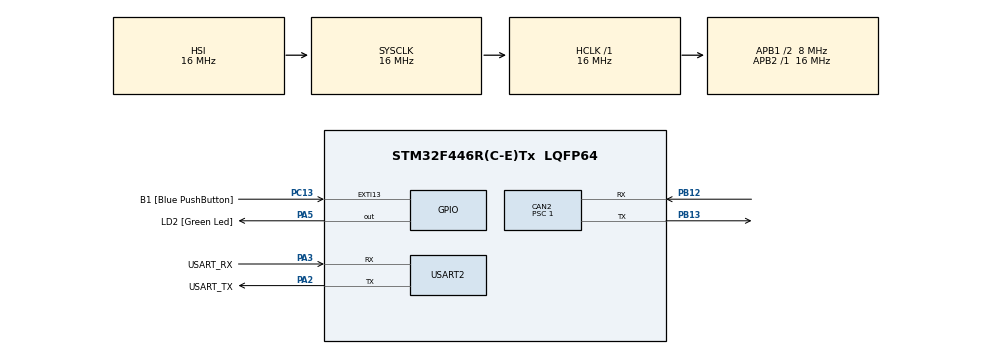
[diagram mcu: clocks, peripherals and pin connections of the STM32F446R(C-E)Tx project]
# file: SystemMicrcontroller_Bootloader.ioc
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Mcu.Family=STM32F4
PC15-OSC32_OUT.Mode=LSE-External-Oscillator
CAN2.CalculateBaudRate=500000
PH0-OSC_IN.Signal=RCC_OSC_IN
RCC.CortexFreq_Value=16000000
CAN2.CalculateTimeBit=2000.00
PC13.Signal=GPXTI13
PA14.GPIO_Label=TCK
PC13.GPIO_Label=B1 [Blue PushButton]
RCC.APB1CLKDivider=RCC_HCLK_DIV2
PC14-OSC32_IN.Signal=RCC_OSC32_IN
PB13.Signal=CAN2_TX
ProjectManager.StackSize=0x400
PA13.Signal=SYS_JTMS-SWDIO
PA3.Mode=Asynchronous
ProjectManager.TargetToolchain=STM32CubeIDE
RCC.HCLKFreq_Value=16000000
RCC.APB2TimFreq_Value=16000000
RCC.USBFreq_Value=168000000
PC15-OSC32_OUT.Signal=RCC_OSC32_OUT
RCC.AHBFreq_Value=16000000
PH0-OSC_IN.Mode=HSE-External-Oscillator
PA5.Signal=GPIO_Output
RCC.HSE_VALUE=8000000
board=NUCLEO-F446RE
RCC.VCOOutputFreq_Value=336000000
RCC.APB2Freq_Value=16000000
PC14-OSC32_IN.Mode=LSE-External-Oscillator
PA14.Mode=Serial_Wire
CAN2.Prescaler=1
CAN2.CalculateTimeQuantum=125.0
PH1-OSC_OUT.Signal=RCC_OSC_OUT
PA13.Mode=Serial_Wire
Mcu.Name=STM32F446R(C-E)Tx
PA2.Signal=USART2_TX
PA13.GPIO_Label=TMS
RCC.FLatency-AdvancedSettings=FLASH_LATENCY_0
PH1-OSC_OUT.Mode=HSE-External-Oscillator
RCC.48MHZClocksFreq_Value=84000000
PB3.Signal=SYS_JTDO-SWO
RCC.SYSCLKFreq_VALUE=16000000
Mcu.Package=LQFP64
PB12.Mode=CAN_Activate
CAN2.BS1=CAN_BS1_13TQ
PA5.GPIO_Label=LD2 [Green Led]
CAN2.BS2=CAN_BS2_2TQ
PC13.GPIO_ModeDefaultEXTI=GPIO_MODE_IT_FALLING
USART2.VirtualMode=VM_ASYNC
PA2.GPIO_Label=USART_TX
PA14.Signal=SYS_JTCK-SWCLK
ProjectManager.HeapSize=0x200
RCC.HSI_VALUE=16000000
RCC.PLLP=RCC_PLLP_DIV4
NVIC.PriorityGroup=NVIC_PRIORITYGROUP_0
RCC.PLLN=336
RCC.APB1TimFreq_Value=16000000
PA2.Mode=Asynchronous
PB13.Mode=CAN_Activate
RCC.APB1Freq_Value=8000000
VP_CRC_VS_CRC.Mode=CRC_Activate
PB12.Signal=CAN2_RX
PA3.GPIO_Label=USART_RX
PA3.Signal=USART2_RX
PB3.GPIO_Label=SWO

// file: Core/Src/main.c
/* USER CODE BEGIN Header */
/**
  ******************************************************************************
  * @file           : main.c
  * @brief          : Main program body
  ******************************************************************************
  * @attention
  *
  * <h2><center>&copy; Copyright (c) 2021 STMicroelectronics.
  * All rights reserved.</center></h2>
  *
  * This software component is licensed by ST under BSD 3-Clause license,
  * the "License"; You may not use this file except in compliance with the
  * License. You may obtain a copy of the License at:
  *                        opensource.org/licenses/BSD-3-Clause
  *
  ******************************************************************************
  */
/* USER CODE END Header */
#include "main.h"
#include "can.h"
#include "crc.h"
#include "usart.h"
#include "gpio.h"

/* USER CODE BEGIN Includes */
#include "SystemTruckBL_main.h"
/* USER CODE END Includes */

void SystemClock_Config(void);

int main(void)
{

  /* MCU Configuration--------------------------------------------------------*/

  /* Reset of all peripherals, Initializes the Flash interface and the Systick. */
  HAL_Init();

  /* Configure the system clock */
  SystemClock_Config();

  /* Initialize all configured peripherals */
  MX_GPIO_Init();
  MX_USART2_UART_Init();
  MX_CAN2_Init();
  MX_CRC_Init();
  /* USER CODE BEGIN 2 */
  SystemTruckBL_main();
  /* USER CODE END 2 */

  /* Infinite loop */
  while (1)
  {

  }
}

void SystemClock_Config(void)
{
  RCC_OscInitTypeDef RCC_OscInitStruct = {0};
  RCC_ClkInitTypeDef RCC_ClkInitStruct = {0};

  /** Configure the main internal regulator output voltage
  */
  __HAL_RCC_PWR_CLK_ENABLE();
  __HAL_PWR_VOLTAGESCALING_CONFIG(PWR_REGULATOR_VOLTAGE_SCALE3);
  /** Initializes the RCC Oscillators according to the specified parameters
  * in the RCC_OscInitTypeDef structure.
  */
  RCC_OscInitStruct.OscillatorType = RCC_OSCILLATORTYPE_HSI;
  RCC_OscInitStruct.HSIState = RCC_HSI_ON;
  RCC_OscInitStruct.HSICalibrationValue = RCC_HSICALIBRATION_DEFAULT;
  RCC_OscInitStruct.PLL.PLLState = RCC_PLL_NONE;
  if (HAL_RCC_OscConfig(&RCC_OscInitStruct) != HAL_OK)
  {
    Error_Handler();
  }
  /** Initializes the CPU, AHB and APB buses clocks
  */
  RCC_ClkInitStruct.ClockType = RCC_CLOCKTYPE_HCLK|RCC_CLOCKTYPE_SYSCLK
                              |RCC_CLOCKTYPE_PCLK1|RCC_CLOCKTYPE_PCLK2;
  RCC_ClkInitStruct.SYSCLKSource = RCC_SYSCLKSOURCE_HSI;
  RCC_ClkInitStruct.AHBCLKDivider = RCC_SYSCLK_DIV1;
  RCC_ClkInitStruct.APB1CLKDivider = RCC_HCLK_DIV2;
  RCC_ClkInitStruct.APB2CLKDivider = RCC_HCLK_DIV1;

  if (HAL_RCC_ClockConfig(&RCC_ClkInitStruct, FLASH_LATENCY_0) != HAL_OK)
  {
    Error_Handler();
  }
}

void Error_Handler(void)
{
  __disable_irq();
  while (1)
  {
  }
}

#ifdef  USE_FULL_ASSERT
/**
  * @brief  Reports the name of the source file and the source line number
  *         where the assert_param error has occurred.
  * @param  file: pointer to the source file name
  * @param  line: assert_param error line source number
  * @retval None
  */
void assert_failed(uint8_t *file, uint32_t line)
{
  /* USER CODE BEGIN 6 */
  /* User can add his own implementation to report the file name and line number,
     ex: printf("Wrong parameters value: file %s on line %d\r\n", file, line) */
	printmsg("Wrong parameters value: file %s on line %d\r\n", file, line);
	Error_Handler();
  /* USER CODE END 6 */
}
#endif /* USE_FULL_ASSERT */

/************************ (C) COPYRIGHT STMicroelectronics *****END OF FILE****/
